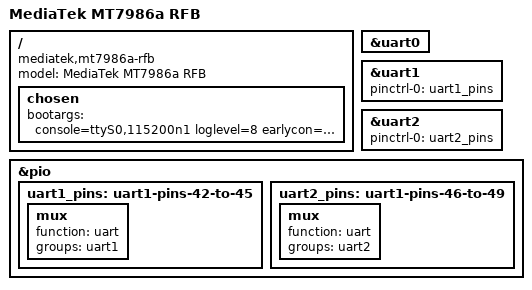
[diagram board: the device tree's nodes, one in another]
// SPDX-License-Identifier: (GPL-2.0 OR MIT)
/*
 * Copyright (C) 2021 MediaTek Inc.
 * Author: Sam.Shih <sam.shih@mediatek.com>
 */

/dts-v1/;
#include "mt7986a.dtsi"

/ {
	model = "MediaTek MT7986a RFB";
	compatible = "mediatek,mt7986a-rfb";
	chosen {
		bootargs = "console=ttyS0,115200n1 loglevel=8  \
				earlycon=uart8250,mmio32,0x11002000";
	};
};

&uart0 {
	status = "okay";
};

&uart1 {
	pinctrl-names = "default";
	pinctrl-0 = <&uart1_pins>;
	status = "okay";
};

&uart2 {
	pinctrl-names = "default";
	pinctrl-0 = <&uart2_pins>;
	status = "okay";
};

&pio {
	uart1_pins: uart1-pins-42-to-45 {
		mux {
			function = "uart";
			groups = "uart1";
		};
	};

	uart2_pins: uart1-pins-46-to-49 {
		mux {
			function = "uart";
			groups = "uart2";
		};
	};
};
